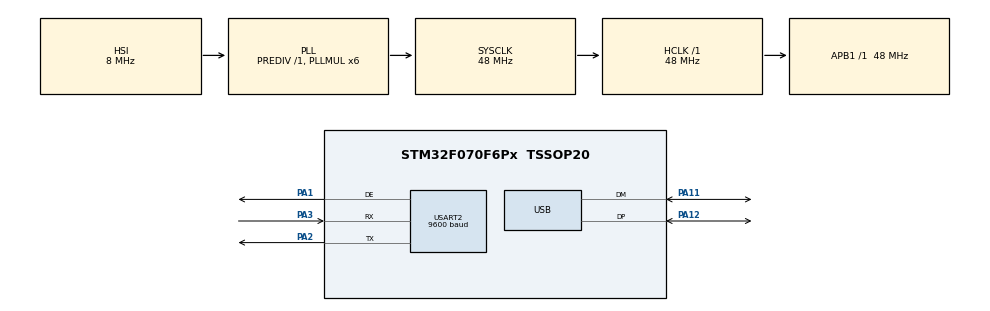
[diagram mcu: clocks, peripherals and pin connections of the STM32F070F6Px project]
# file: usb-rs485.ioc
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Mcu.Family=STM32F0
Mcu.Name=STM32F070F6Px
Mcu.Package=TSSOP20
NVIC.USART2_IRQn=true\:0\:0\:false\:false\:true
NVIC.USB_IRQn=true\:0\:0\:false\:false\:true
PA1.Mode=Hardware Flow Control (RS485)
PA1.Signal=USART2_DE
PA11.Mode=Device
PA11.Signal=USB_DM
PA12.Mode=Device
PA12.Signal=USB_DP
PA13.Mode=Serial-WireDebug
PA13.Signal=SYS_SWDIO
PA14.Mode=Serial-WireDebug
PA14.Signal=SYS_SWCLK
PA2.Mode=Asynchronous
PA2.Signal=USART2_TX
PA3.Mode=Asynchronous
PA3.Signal=USART2_RX
ProjectManager.HeapSize=0x200
ProjectManager.StackSize=0x400
ProjectManager.TargetToolchain=MDK-ARM V5
RCC.AHBFreq_Value=48000000
RCC.APB1Freq_Value=48000000
RCC.APB1TimFreq_Value=48000000
RCC.HCLKFreq_Value=48000000
RCC.PLLMUL=RCC_PLL_MUL6
RCC.SYSCLKFreq_VALUE=48000000
RCC.SYSCLKSource=RCC_SYSCLKSOURCE_PLLCLK
USART2.BaudRate=9600
USART2.WordLength=UART_WORDLENGTH_8B
USB_DEVICE.CLASS_NAME_FS=CDC
USB_DEVICE.USBD_HandleTypeDef=hUsbDeviceFS
USB_DEVICE.VirtualMode=Cdc
USB_DEVICE.VirtualModeFS=Cdc_FS
VP_SYS_VS_PINREMAP.Mode=PINREMAP
VP_USB_DEVICE_VS_USB_DEVICE_CDC_FS.Mode=CDC_FS
board=usb-rs485

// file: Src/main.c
/**
  ******************************************************************************
  * File Name          : main.c
  * Description        : Main program body
  ******************************************************************************
  *
  * COPYRIGHT(c) 2016 STMicroelectronics
  *
  * Redistribution and use in source and binary forms, with or without modification,
  * are permitted provided that the following conditions are met:
  *   1. Redistributions of source code must retain the above copyright notice,
  *      this list of conditions and the following disclaimer.
  *   2. Redistributions in binary form must reproduce the above copyright notice,
  *      this list of conditions and the following disclaimer in the documentation
  *      and/or other materials provided with the distribution.
  *   3. Neither the name of STMicroelectronics nor the names of its contributors
  *      may be used to endorse or promote products derived from this software
  *      without specific prior written permission.
  *
  * THIS SOFTWARE IS PROVIDED BY THE COPYRIGHT HOLDERS AND CONTRIBUTORS "AS IS"
  * AND ANY EXPRESS OR IMPLIED WARRANTIES, INCLUDING, BUT NOT LIMITED TO, THE
  * IMPLIED WARRANTIES OF MERCHANTABILITY AND FITNESS FOR A PARTICULAR PURPOSE ARE
  * DISCLAIMED. IN NO EVENT SHALL THE COPYRIGHT HOLDER OR CONTRIBUTORS BE LIABLE
  * FOR ANY DIRECT, INDIRECT, INCIDENTAL, SPECIAL, EXEMPLARY, OR CONSEQUENTIAL
  * DAMAGES (INCLUDING, BUT NOT LIMITED TO, PROCUREMENT OF SUBSTITUTE GOODS OR
  * SERVICES; LOSS OF USE, DATA, OR PROFITS; OR BUSINESS INTERRUPTION) HOWEVER
  * CAUSED AND ON ANY THEORY OF LIABILITY, WHETHER IN CONTRACT, STRICT LIABILITY,
  * OR TORT (INCLUDING NEGLIGENCE OR OTHERWISE) ARISING IN ANY WAY OUT OF THE USE
  * OF THIS SOFTWARE, EVEN IF ADVISED OF THE POSSIBILITY OF SUCH DAMAGE.
  *
  ******************************************************************************
  */
#include "stm32f0xx_hal.h"
#include "usb_device.h"
#include "usbd_cdc_if.h"

UART_HandleTypeDef huart2;

uint8_t aRxBuffer[16];
uint8_t aTxBuffer[16];

/* USER CODE BEGIN PV */
/* Private variables ---------------------------------------------------------*/

/* USER CODE END PV */

void SystemClock_Config(void);
static void MX_GPIO_Init(void);
static void MX_USART2_UART_Init(void);

/* USER CODE BEGIN PFP */
/* Private function prototypes -----------------------------------------------*/

/* USER CODE END PFP */

int main(void)
{

//	HAL_StatusTypeDef status;
  /* USER CODE BEGIN 1 */
  //uint8_t HiMsg[]="hello\r\n";
  /* USER CODE END 1 */

	int i;

  /* MCU Configuration----------------------------------------------------------*/

  /* Reset of all peripherals, Initializes the Flash interface and the Systick. */
  HAL_Init();

  /* Configure the system clock */
  SystemClock_Config();

  /* Initialize all configured peripherals */
  MX_GPIO_Init();
  MX_USART2_UART_Init();
  MX_USB_DEVICE_Init();

  /* USER CODE BEGIN 2 */
  HAL_Delay(500);
  /* USER CODE END 2 */

  /* Infinite loop */
  while (1)
  {
//	CDC_Transmit_FS(HiMsg,strlen(HiMsg));
//  HAL_Delay(200);
		if (HAL_UART_Receive_IT(&huart2, aRxBuffer, 1) == HAL_OK)
		//if (HAL_UART_Receive(&huart2, &aRxBuffer, 1, 1) == HAL_OK)
		{
			for (i = 0; i<huart2.RxXferSize; i++)	aTxBuffer[i] = aRxBuffer[i];
			//HAL_Delay(1);
			CDC_Transmit_FS(aTxBuffer,huart2.RxXferSize);
		}

  }

}

/** System Clock Configuration
*/
void SystemClock_Config(void)
{

  RCC_OscInitTypeDef RCC_OscInitStruct;
  RCC_ClkInitTypeDef RCC_ClkInitStruct;
  RCC_PeriphCLKInitTypeDef PeriphClkInit;

  RCC_OscInitStruct.OscillatorType = RCC_OSCILLATORTYPE_HSI;
  RCC_OscInitStruct.HSIState = RCC_HSI_ON;
  RCC_OscInitStruct.HSICalibrationValue = 16;
  RCC_OscInitStruct.PLL.PLLState = RCC_PLL_ON;
  RCC_OscInitStruct.PLL.PLLSource = RCC_PLLSOURCE_HSI;
  RCC_OscInitStruct.PLL.PLLMUL = RCC_PLL_MUL6;
  RCC_OscInitStruct.PLL.PREDIV = RCC_PREDIV_DIV1;
  HAL_RCC_OscConfig(&RCC_OscInitStruct);

  RCC_ClkInitStruct.ClockType = RCC_CLOCKTYPE_HCLK|RCC_CLOCKTYPE_SYSCLK
                              |RCC_CLOCKTYPE_PCLK1;
  RCC_ClkInitStruct.SYSCLKSource = RCC_SYSCLKSOURCE_PLLCLK;
  RCC_ClkInitStruct.AHBCLKDivider = RCC_SYSCLK_DIV1;
  RCC_ClkInitStruct.APB1CLKDivider = RCC_HCLK_DIV1;
  HAL_RCC_ClockConfig(&RCC_ClkInitStruct, FLASH_LATENCY_1);

  PeriphClkInit.PeriphClockSelection = RCC_PERIPHCLK_USB;
  PeriphClkInit.UsbClockSelection = RCC_USBCLKSOURCE_PLL;
  HAL_RCCEx_PeriphCLKConfig(&PeriphClkInit);

  HAL_SYSTICK_Config(HAL_RCC_GetHCLKFreq()/1000);

  HAL_SYSTICK_CLKSourceConfig(SYSTICK_CLKSOURCE_HCLK);

  /* SysTick_IRQn interrupt configuration */
  HAL_NVIC_SetPriority(SysTick_IRQn, 0, 0);
}

/* USART2 init function */
void MX_USART2_UART_Init(void)
{

  huart2.Instance = USART2;
  huart2.Init.BaudRate = 9600;
  huart2.Init.WordLength = UART_WORDLENGTH_8B;
  huart2.Init.StopBits = UART_STOPBITS_1;
  huart2.Init.Parity = UART_PARITY_NONE;
  huart2.Init.Mode = UART_MODE_TX_RX;
  huart2.Init.HwFlowCtl = UART_HWCONTROL_NONE;
  huart2.Init.OverSampling = UART_OVERSAMPLING_16;
  huart2.Init.OneBitSampling = UART_ONE_BIT_SAMPLE_DISABLE;
  huart2.AdvancedInit.AdvFeatureInit = UART_ADVFEATURE_NO_INIT;
  HAL_RS485Ex_Init(&huart2, UART_DE_POLARITY_HIGH, 0, 0);

}

/** Configure pins as
        * Analog
        * Input
        * Output
        * EVENT_OUT
        * EXTI
*/
void MX_GPIO_Init(void)
{

  /* GPIO Ports Clock Enable */
  __HAL_RCC_GPIOA_CLK_ENABLE();

}

/************************ (C) COPYRIGHT STMicroelectronics *****END OF FILE****/
